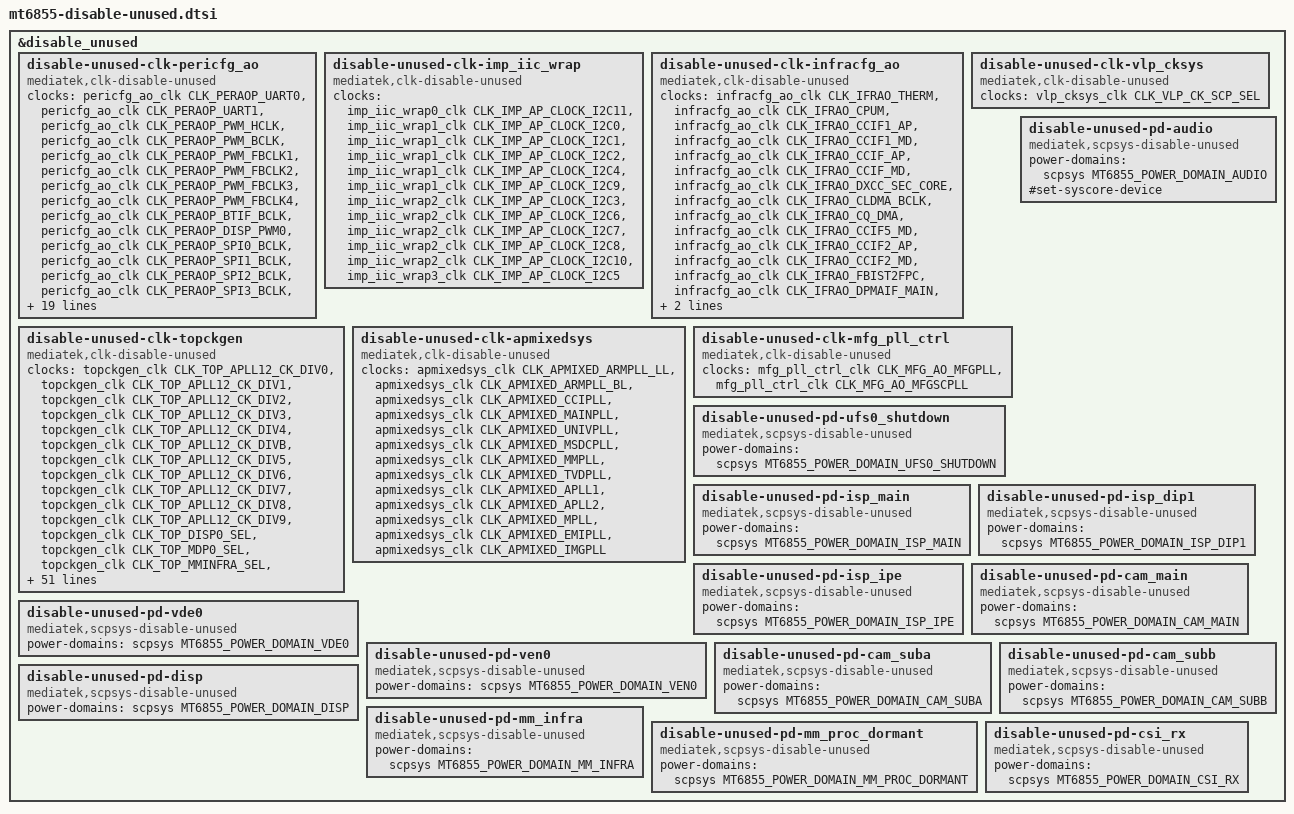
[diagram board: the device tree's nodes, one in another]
// SPDX-License-Identifier: (GPL-2.0 OR MIT)
/*
 * Copyright (C) 2021 MediaTek Inc.
 * Author: Owen Chen <owen.chen@mediatek.com>
 */

&disable_unused {
	status = "okay";
	disable-unused-clk-pericfg_ao {
		compatible = "mediatek,clk-disable-unused";
		clocks =
			<&pericfg_ao_clk CLK_PERAOP_UART0>,
			<&pericfg_ao_clk CLK_PERAOP_UART1>,
			<&pericfg_ao_clk CLK_PERAOP_PWM_HCLK>,
			<&pericfg_ao_clk CLK_PERAOP_PWM_BCLK>,
			<&pericfg_ao_clk CLK_PERAOP_PWM_FBCLK1>,
			<&pericfg_ao_clk CLK_PERAOP_PWM_FBCLK2>,
			<&pericfg_ao_clk CLK_PERAOP_PWM_FBCLK3>,
			<&pericfg_ao_clk CLK_PERAOP_PWM_FBCLK4>,
			<&pericfg_ao_clk CLK_PERAOP_BTIF_BCLK>,
			<&pericfg_ao_clk CLK_PERAOP_DISP_PWM0>,
			<&pericfg_ao_clk CLK_PERAOP_SPI0_BCLK>,
			<&pericfg_ao_clk CLK_PERAOP_SPI1_BCLK>,
			<&pericfg_ao_clk CLK_PERAOP_SPI2_BCLK>,
			<&pericfg_ao_clk CLK_PERAOP_SPI3_BCLK>,
			<&pericfg_ao_clk CLK_PERAOP_SPI4_BCLK>,
			<&pericfg_ao_clk CLK_PERAOP_SPI5_BCLK>,
			<&pericfg_ao_clk CLK_PERAOP_SPI6_BCLK>,
			<&pericfg_ao_clk CLK_PERAOP_SPI7_BCLK>,
			<&pericfg_ao_clk CLK_PERAOP_APDMA>,
			<&pericfg_ao_clk CLK_PERAOP_USB_PHY>,
			<&pericfg_ao_clk CLK_PERAOP_USB_SYS>,
			<&pericfg_ao_clk CLK_PERAOP_USB_DMA_BUS>,
			<&pericfg_ao_clk CLK_PERAOP_USB_MCU_BUS>,
			<&pericfg_ao_clk CLK_PERAOP_MSDC1>,
			<&pericfg_ao_clk CLK_PERAOP_MSDC1_HCLK>,
			<&pericfg_ao_clk CLK_PERAOP_FMSDC50>,
			<&pericfg_ao_clk CLK_PERAOP_FMSDC50_HCLK>,
			<&pericfg_ao_clk CLK_PERAOP_FAES_MSDCFDE>,
			<&pericfg_ao_clk CLK_PERAOP_MSDC50_XCLK>,
			<&pericfg_ao_clk CLK_PERAOP_MSDC50_HCLK>,
			<&pericfg_ao_clk CLK_PERAO_AUDIO_SLV_CK_PERI>,
			<&pericfg_ao_clk CLK_PERAO_AUDIO_MST_CK_PERI>,
			<&pericfg_ao_clk CLK_PERAO_INTBUS_CK_PERI>;
	};

	disable-unused-clk-imp_iic_wrap {
		compatible = "mediatek,clk-disable-unused";
		clocks =
			<&imp_iic_wrap0_clk CLK_IMP_AP_CLOCK_I2C11>,
			<&imp_iic_wrap1_clk CLK_IMP_AP_CLOCK_I2C0>,
			<&imp_iic_wrap1_clk CLK_IMP_AP_CLOCK_I2C1>,
			<&imp_iic_wrap1_clk CLK_IMP_AP_CLOCK_I2C2>,
			<&imp_iic_wrap1_clk CLK_IMP_AP_CLOCK_I2C4>,
			<&imp_iic_wrap1_clk CLK_IMP_AP_CLOCK_I2C9>,
			<&imp_iic_wrap2_clk CLK_IMP_AP_CLOCK_I2C3>,
			<&imp_iic_wrap2_clk CLK_IMP_AP_CLOCK_I2C6>,
			<&imp_iic_wrap2_clk CLK_IMP_AP_CLOCK_I2C7>,
			<&imp_iic_wrap2_clk CLK_IMP_AP_CLOCK_I2C8>,
			<&imp_iic_wrap2_clk CLK_IMP_AP_CLOCK_I2C10>,
			<&imp_iic_wrap3_clk CLK_IMP_AP_CLOCK_I2C5>;
	};

	disable-unused-clk-infracfg_ao {
		compatible = "mediatek,clk-disable-unused";
		clocks =
			<&infracfg_ao_clk CLK_IFRAO_THERM>,
			<&infracfg_ao_clk CLK_IFRAO_CPUM>,
			<&infracfg_ao_clk CLK_IFRAO_CCIF1_AP>,
			<&infracfg_ao_clk CLK_IFRAO_CCIF1_MD>,
			<&infracfg_ao_clk CLK_IFRAO_CCIF_AP>,
			<&infracfg_ao_clk CLK_IFRAO_CCIF_MD>,
			<&infracfg_ao_clk CLK_IFRAO_DXCC_SEC_CORE>,
			<&infracfg_ao_clk CLK_IFRAO_CLDMA_BCLK>,
			<&infracfg_ao_clk CLK_IFRAO_CQ_DMA>,
			<&infracfg_ao_clk CLK_IFRAO_CCIF5_MD>,
			<&infracfg_ao_clk CLK_IFRAO_CCIF2_AP>,
			<&infracfg_ao_clk CLK_IFRAO_CCIF2_MD>,
			<&infracfg_ao_clk CLK_IFRAO_FBIST2FPC>,
			<&infracfg_ao_clk CLK_IFRAO_DPMAIF_MAIN>,
			<&infracfg_ao_clk CLK_IFRAO_CCIF4_MD>,
			<&infracfg_ao_clk CLK_IFRAO_RG_MMW_DPMAIF26M_CK>;
	};

	disable-unused-clk-vlp_cksys {
		compatible = "mediatek,clk-disable-unused";
		clocks =
			<&vlp_cksys_clk CLK_VLP_CK_SCP_SEL>;
	};

	disable-unused-clk-topckgen {
		compatible = "mediatek,clk-disable-unused";
		clocks =
			<&topckgen_clk CLK_TOP_APLL12_CK_DIV0>,
			<&topckgen_clk CLK_TOP_APLL12_CK_DIV1>,
			<&topckgen_clk CLK_TOP_APLL12_CK_DIV2>,
			<&topckgen_clk CLK_TOP_APLL12_CK_DIV3>,
			<&topckgen_clk CLK_TOP_APLL12_CK_DIV4>,
			<&topckgen_clk CLK_TOP_APLL12_CK_DIVB>,
			<&topckgen_clk CLK_TOP_APLL12_CK_DIV5>,
			<&topckgen_clk CLK_TOP_APLL12_CK_DIV6>,
			<&topckgen_clk CLK_TOP_APLL12_CK_DIV7>,
			<&topckgen_clk CLK_TOP_APLL12_CK_DIV8>,
			<&topckgen_clk CLK_TOP_APLL12_CK_DIV9>,
			<&topckgen_clk CLK_TOP_DISP0_SEL>,
			<&topckgen_clk CLK_TOP_MDP0_SEL>,
			<&topckgen_clk CLK_TOP_MMINFRA_SEL>,
			<&topckgen_clk CLK_TOP_MMUP_SEL>,
			<&topckgen_clk CLK_TOP_CAMTG_SEL>,
			<&topckgen_clk CLK_TOP_CAMTG2_SEL>,
			<&topckgen_clk CLK_TOP_CAMTG3_SEL>,
			<&topckgen_clk CLK_TOP_CAMTG4_SEL>,
			<&topckgen_clk CLK_TOP_CAMTG5_SEL>,
			<&topckgen_clk CLK_TOP_CAMTG6_SEL>,
			<&topckgen_clk CLK_TOP_SPI_SEL>,
			<&topckgen_clk CLK_TOP_MSDC_0P_MACRO_SEL>,
			<&topckgen_clk CLK_TOP_MSDC50_0_HCLK_SEL>,
			<&topckgen_clk CLK_TOP_MSDC50_0_SEL>,
			<&topckgen_clk CLK_TOP_AES_MSDCFDE_SEL>,
			<&topckgen_clk CLK_TOP_MSDC_MACRO_SEL>,
			<&topckgen_clk CLK_TOP_MSDC30_1_SEL>,
			<&topckgen_clk CLK_TOP_AUDIO_SEL>,
			<&topckgen_clk CLK_TOP_AUD_INTBUS_SEL>,
			<&topckgen_clk CLK_TOP_DISP_PWM_SEL>,
			<&topckgen_clk CLK_TOP_USB_TOP_SEL>,
			<&topckgen_clk CLK_TOP_USB_XHCI_SEL>,
			<&topckgen_clk CLK_TOP_I2C_SEL>,
			<&topckgen_clk CLK_TOP_SENINF_SEL>,
			<&topckgen_clk CLK_TOP_SENINF1_SEL>,
			<&topckgen_clk CLK_TOP_SENINF2_SEL>,
			<&topckgen_clk CLK_TOP_SENINF3_SEL>,
			<&topckgen_clk CLK_TOP_AUD_ENGEN1_SEL>,
			<&topckgen_clk CLK_TOP_AUD_ENGEN2_SEL>,
			<&topckgen_clk CLK_TOP_AES_UFSFDE_SEL>,
			<&topckgen_clk CLK_TOP_U_SEL>,
			<&topckgen_clk CLK_TOP_U_MBIST_SEL>,
			<&topckgen_clk CLK_TOP_AUD_1_SEL>,
			<&topckgen_clk CLK_TOP_AUD_2_SEL>,
			<&topckgen_clk CLK_TOP_VENC_SEL>,
			<&topckgen_clk CLK_TOP_VDEC_SEL>,
			<&topckgen_clk CLK_TOP_PWM_SEL>,
			<&topckgen_clk CLK_TOP_AUDIO_H_SEL>,
			<&topckgen_clk CLK_TOP_DSI_OCC_SEL>,
			<&topckgen_clk CLK_TOP_IMG1_SEL>,
			<&topckgen_clk CLK_TOP_IPE_SEL>,
			<&topckgen_clk CLK_TOP_CAM_SEL>,
			<&topckgen_clk CLK_TOP_CAMTM_SEL>,
			<&topckgen_clk CLK_TOP_MSDC_1P_RX_SEL>,
			<&topckgen_clk CLK_TOP_APLL_I2S0_MCK_SEL>,
			<&topckgen_clk CLK_TOP_APLL_I2S1_MCK_SEL>,
			<&topckgen_clk CLK_TOP_APLL_I2S2_MCK_SEL>,
			<&topckgen_clk CLK_TOP_APLL_I2S3_MCK_SEL>,
			<&topckgen_clk CLK_TOP_APLL_I2S4_MCK_SEL>,
			<&topckgen_clk CLK_TOP_APLL_I2S5_MCK_SEL>,
			<&topckgen_clk CLK_TOP_APLL_I2S6_MCK_SEL>,
			<&topckgen_clk CLK_TOP_APLL_I2S7_MCK_SEL>,
			<&topckgen_clk CLK_TOP_APLL_I2S8_MCK_SEL>,
			<&topckgen_clk CLK_TOP_APLL_I2S9_MCK_SEL>;
	};

	disable-unused-clk-apmixedsys {
		compatible = "mediatek,clk-disable-unused";
		clocks =
			<&apmixedsys_clk CLK_APMIXED_ARMPLL_LL>,
			<&apmixedsys_clk CLK_APMIXED_ARMPLL_BL>,
			<&apmixedsys_clk CLK_APMIXED_CCIPLL>,
			<&apmixedsys_clk CLK_APMIXED_MAINPLL>,
			<&apmixedsys_clk CLK_APMIXED_UNIVPLL>,
			<&apmixedsys_clk CLK_APMIXED_MSDCPLL>,
			<&apmixedsys_clk CLK_APMIXED_MMPLL>,
			<&apmixedsys_clk CLK_APMIXED_TVDPLL>,
			<&apmixedsys_clk CLK_APMIXED_APLL1>,
			<&apmixedsys_clk CLK_APMIXED_APLL2>,
			<&apmixedsys_clk CLK_APMIXED_MPLL>,
			<&apmixedsys_clk CLK_APMIXED_EMIPLL>,
			<&apmixedsys_clk CLK_APMIXED_IMGPLL>;
	};

	disable-unused-clk-mfg_pll_ctrl {
		compatible = "mediatek,clk-disable-unused";
		clocks =
			<&mfg_pll_ctrl_clk CLK_MFG_AO_MFGPLL>,
			<&mfg_pll_ctrl_clk CLK_MFG_AO_MFGSCPLL>;
	};

	disable-unused-pd-ufs0_shutdown {
		compatible = "mediatek,scpsys-disable-unused";
		power-domains = <&scpsys MT6855_POWER_DOMAIN_UFS0_SHUTDOWN>;
	};

	disable-unused-pd-audio {
		compatible = "mediatek,scpsys-disable-unused";
		power-domains = <&scpsys MT6855_POWER_DOMAIN_AUDIO>;
		#set-syscore-device;
	};

	disable-unused-pd-isp_main {
		compatible = "mediatek,scpsys-disable-unused";
		power-domains = <&scpsys MT6855_POWER_DOMAIN_ISP_MAIN>;
	};

	disable-unused-pd-isp_dip1 {
		compatible = "mediatek,scpsys-disable-unused";
		power-domains = <&scpsys MT6855_POWER_DOMAIN_ISP_DIP1>;
	};

	disable-unused-pd-isp_ipe {
		compatible = "mediatek,scpsys-disable-unused";
		power-domains = <&scpsys MT6855_POWER_DOMAIN_ISP_IPE>;
	};

	disable-unused-pd-vde0 {
		compatible = "mediatek,scpsys-disable-unused";
		power-domains = <&scpsys MT6855_POWER_DOMAIN_VDE0>;
	};

	disable-unused-pd-ven0 {
		compatible = "mediatek,scpsys-disable-unused";
		power-domains = <&scpsys MT6855_POWER_DOMAIN_VEN0>;
	};

	disable-unused-pd-cam_main {
		compatible = "mediatek,scpsys-disable-unused";
		power-domains = <&scpsys MT6855_POWER_DOMAIN_CAM_MAIN>;
	};

	disable-unused-pd-cam_suba {
		compatible = "mediatek,scpsys-disable-unused";
		power-domains = <&scpsys MT6855_POWER_DOMAIN_CAM_SUBA>;
	};

	disable-unused-pd-cam_subb {
		compatible = "mediatek,scpsys-disable-unused";
		power-domains = <&scpsys MT6855_POWER_DOMAIN_CAM_SUBB>;
	};

	disable-unused-pd-disp {
		compatible = "mediatek,scpsys-disable-unused";
		power-domains = <&scpsys MT6855_POWER_DOMAIN_DISP>;
	};

	disable-unused-pd-mm_infra {
		compatible = "mediatek,scpsys-disable-unused";
		power-domains = <&scpsys MT6855_POWER_DOMAIN_MM_INFRA>;
	};

	disable-unused-pd-mm_proc_dormant {
		compatible = "mediatek,scpsys-disable-unused";
		power-domains = <&scpsys MT6855_POWER_DOMAIN_MM_PROC_DORMANT>;
	};

	disable-unused-pd-csi_rx {
		compatible = "mediatek,scpsys-disable-unused";
		power-domains = <&scpsys MT6855_POWER_DOMAIN_CSI_RX>;
	};
};
